# PIC32MX370F512L register map
Registers are 32-bit, access not given, reset 0x0 unless marked. A register's access mark holds for its fields unless they carry their own. Offsets are from the block's base; [hi:lo] are bit positions; {n}, {i} and the like mark numbered series; 'fields as' and 'values as' point back to an identical list.

## PMP — PMP peripheral
Base 0xBF807000
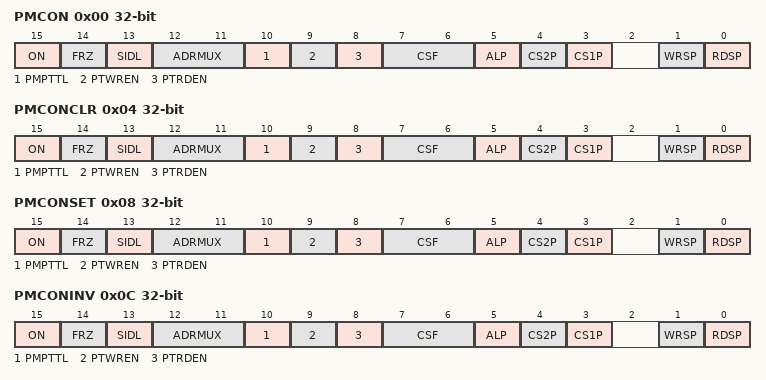
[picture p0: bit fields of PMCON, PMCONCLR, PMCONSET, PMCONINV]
0x00 PMCON
  [15] ON, [14] FRZ, [13] SIDL, [12:11] ADRMUX, [10] PMPTTL, [9] PTWREN, [8] PTRDEN, [7:6] CSF, [5] ALP, [4] CS2P, [3] CS1P, [1] WRSP, [0] RDSP
0x04 PMCONCLR
  fields as PMCON
0x08 PMCONSET
  fields as PMCON
0x0C PMCONINV
  fields as PMCON
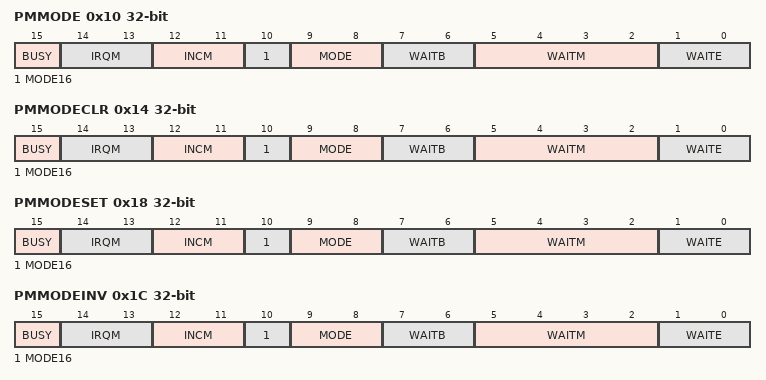
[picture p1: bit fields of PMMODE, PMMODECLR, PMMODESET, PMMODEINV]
0x10 PMMODE
  [15] BUSY, [14:13] IRQM, [12:11] INCM, [10] MODE16, [9:8] MODE, [7:6] WAITB, [5:2] WAITM, [1:0] WAITE
0x14 PMMODECLR
  fields as PMMODE
0x18 PMMODESET
  fields as PMMODE
0x1C PMMODEINV
  fields as PMMODE
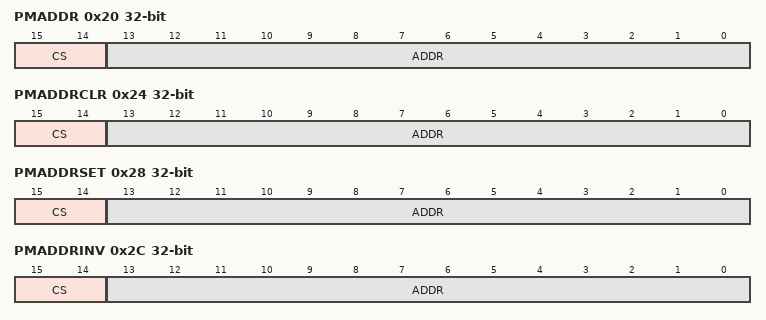
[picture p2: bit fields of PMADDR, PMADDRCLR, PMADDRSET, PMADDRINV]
0x20 PMADDR
  [15:14] CS, [13:0] ADDR
0x24 PMADDRCLR
  [15:14] CS, [13:0] ADDR
0x28 PMADDRSET
  [15:14] CS, [13:0] ADDR
0x2C PMADDRINV
  [15:14] CS, [13:0] ADDR
0x30 PMDOUT
  [31:0] DATAOUT
0x34 PMDOUTCLR
  [31:0] DATAOUT
0x38 PMDOUTSET
  [31:0] DATAOUT
0x3C PMDOUTINV
  [31:0] DATAOUT
0x40 PMDIN
  [31:0] DATAIN
0x44 PMDINCLR
  [31:0] DATAIN
0x48 PMDINSET
  [31:0] DATAIN
0x4C PMDININV
  [31:0] DATAIN
0x50 PMAEN
  [15:0] PTEN
0x54 PMAENCLR
  [15:0] PTEN
0x58 PMAENSET
  [15:0] PTEN
0x5C PMAENINV
  [15:0] PTEN
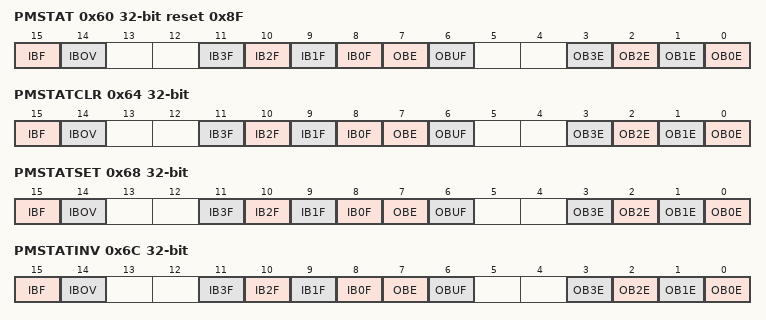
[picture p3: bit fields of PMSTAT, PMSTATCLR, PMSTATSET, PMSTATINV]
0x60 PMSTAT reset 0x8F
  [15] IBF, [14] IBOV, [n+8] IB{n}F (n=0..3), [7] OBE, [6] OBUF, [n] OB{n}E (n=0..3)
0x64 PMSTATCLR
  fields as PMSTAT
0x68 PMSTATSET
  fields as PMSTAT
0x6C PMSTATINV
  fields as PMSTAT

## ADC10 — ADC10 peripheral
Base 0xBF809000
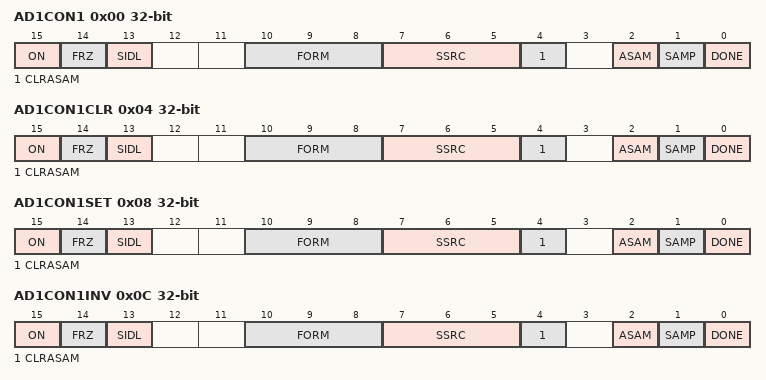
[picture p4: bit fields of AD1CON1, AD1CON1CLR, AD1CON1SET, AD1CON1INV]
0x00 AD1CON1
  [15] ON, [14] FRZ, [13] SIDL, [10:8] FORM, [7:5] SSRC, [4] CLRASAM, [2] ASAM, [1] SAMP, [0] DONE
0x04 AD1CON1CLR
  fields as AD1CON1
0x08 AD1CON1SET
  fields as AD1CON1
0x0C AD1CON1INV
  fields as AD1CON1
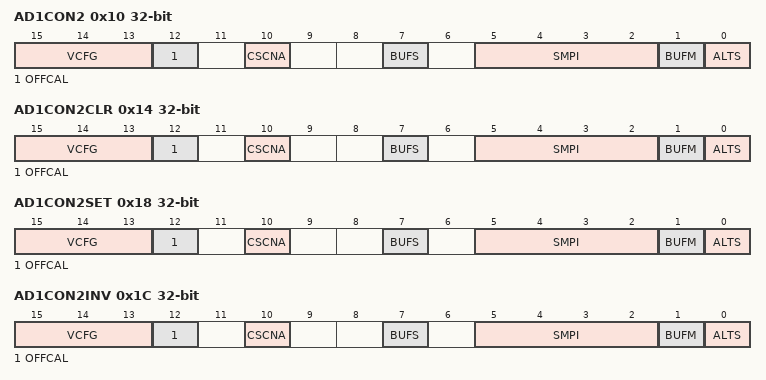
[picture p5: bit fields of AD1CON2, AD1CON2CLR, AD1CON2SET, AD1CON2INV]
0x10 AD1CON2
  [15:13] VCFG, [12] OFFCAL, [10] CSCNA, [7] BUFS, [5:2] SMPI, [1] BUFM, [0] ALTS
0x14 AD1CON2CLR
  fields as AD1CON2
0x18 AD1CON2SET
  fields as AD1CON2
0x1C AD1CON2INV
  fields as AD1CON2
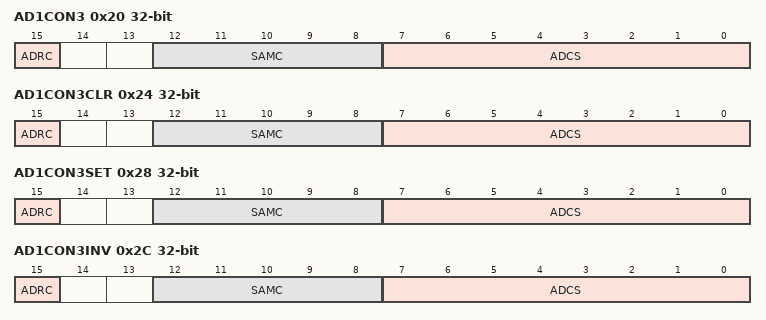
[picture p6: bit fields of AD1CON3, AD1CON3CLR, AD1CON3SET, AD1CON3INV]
0x20 AD1CON3
  [15] ADRC, [12:8] SAMC, [7:0] ADCS
0x24 AD1CON3CLR
  [15] ADRC, [12:8] SAMC, [7:0] ADCS
0x28 AD1CON3SET
  [15] ADRC, [12:8] SAMC, [7:0] ADCS
0x2C AD1CON3INV
  [15] ADRC, [12:8] SAMC, [7:0] ADCS
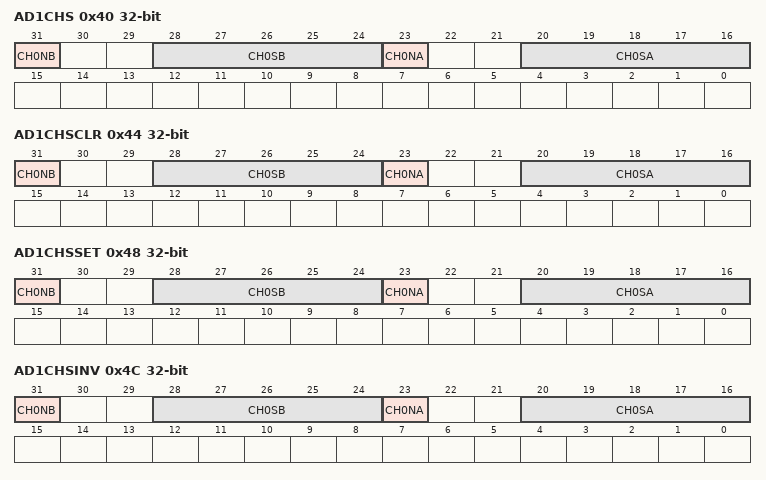
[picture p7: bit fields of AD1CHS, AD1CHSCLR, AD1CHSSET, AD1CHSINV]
0x40 AD1CHS
  [31] CH0NB, [28:24] CH0SB, [23] CH0NA, [20:16] CH0SA
0x44 AD1CHSCLR
  [31] CH0NB, [28:24] CH0SB, [23] CH0NA, [20:16] CH0SA
0x48 AD1CHSSET
  [31] CH0NB, [28:24] CH0SB, [23] CH0NA, [20:16] CH0SA
0x4C AD1CHSINV
  [31] CH0NB, [28:24] CH0SB, [23] CH0NA, [20:16] CH0SA
0x50 AD1CSSL
  [30:0] CSSL
0x54 AD1CSSLCLR
  [30:0] CSSL
0x58 AD1CSSLSET
  [30:0] CSSL
0x5C AD1CSSLINV
  [30:0] CSSL
{0x70+0x10*i} ADC1BUF{i} (i=0..9)
0x110 ADC1BUFA
0x120 ADC1BUFB
0x130 ADC1BUFC
0x140 ADC1BUFD
0x150 ADC1BUFE
0x160 ADC1BUFF

## CVR — CVR peripheral
Base 0xBF809800
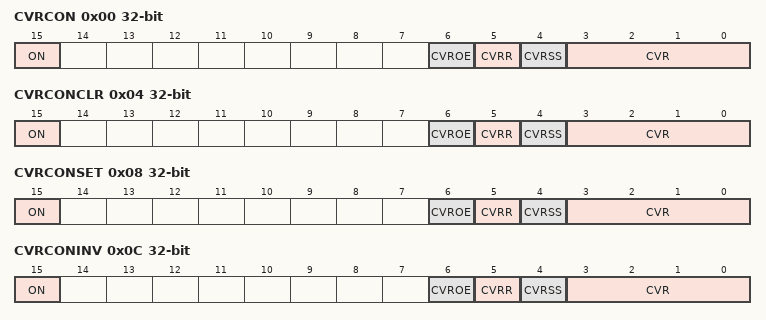
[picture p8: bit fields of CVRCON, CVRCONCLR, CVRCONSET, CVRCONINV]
0x00 CVRCON
  [15] ON, [6] CVROE, [5] CVRR, [4] CVRSS, [3:0] CVR
0x04 CVRCONCLR
  [15] ON, [6] CVROE, [5] CVRR, [4] CVRSS, [3:0] CVR
0x08 CVRCONSET
  [15] ON, [6] CVROE, [5] CVRR, [4] CVRSS, [3:0] CVR
0x0C CVRCONINV
  [15] ON, [6] CVROE, [5] CVRR, [4] CVRSS, [3:0] CVR

## CMP1 — CMP1 peripheral
Base 0xBF80A000
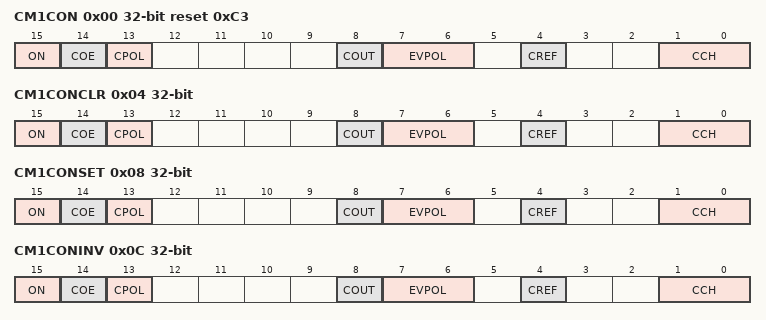
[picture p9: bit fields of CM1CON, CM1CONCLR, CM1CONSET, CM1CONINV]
0x00 CM1CON reset 0xC3
  [15] ON, [14] COE, [13] CPOL, [8] COUT, [7:6] EVPOL, [4] CREF, [1:0] CCH
0x04 CM1CONCLR
  fields as CM1CON
0x08 CM1CONSET
  fields as CM1CON
0x0C CM1CONINV
  fields as CM1CON

## CMP2 — CMP2 peripheral
Base 0xBF80A010
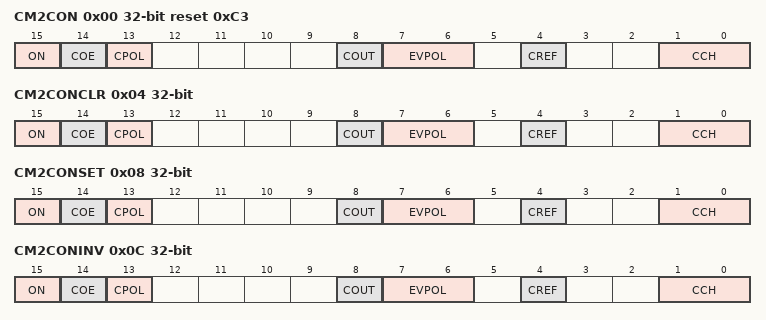
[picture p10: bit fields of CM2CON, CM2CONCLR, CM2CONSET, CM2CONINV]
0x00 CM2CON reset 0xC3
  [15] ON, [14] COE, [13] CPOL, [8] COUT, [7:6] EVPOL, [4] CREF, [1:0] CCH
0x04 CM2CONCLR
  fields as CM2CON
0x08 CM2CONSET
  fields as CM2CON
0x0C CM2CONINV
  fields as CM2CON

## CMP — CMP peripheral
Base 0xBF80A060
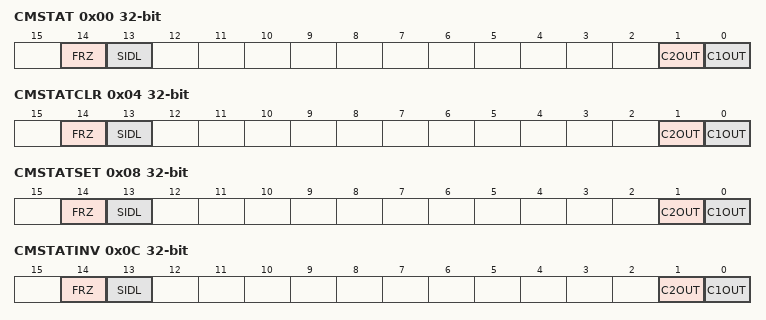
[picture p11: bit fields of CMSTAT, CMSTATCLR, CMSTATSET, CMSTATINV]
0x00 CMSTAT
  [14] FRZ, [13] SIDL, [1] C2OUT, [0] C1OUT
0x04 CMSTATCLR
  [14] FRZ, [13] SIDL, [1] C2OUT, [0] C1OUT
0x08 CMSTATSET
  [14] FRZ, [13] SIDL, [1] C2OUT, [0] C1OUT
0x0C CMSTATINV
  [14] FRZ, [13] SIDL, [1] C2OUT, [0] C1OUT

## CTMU — CTMU peripheral
Base 0xBF80A200
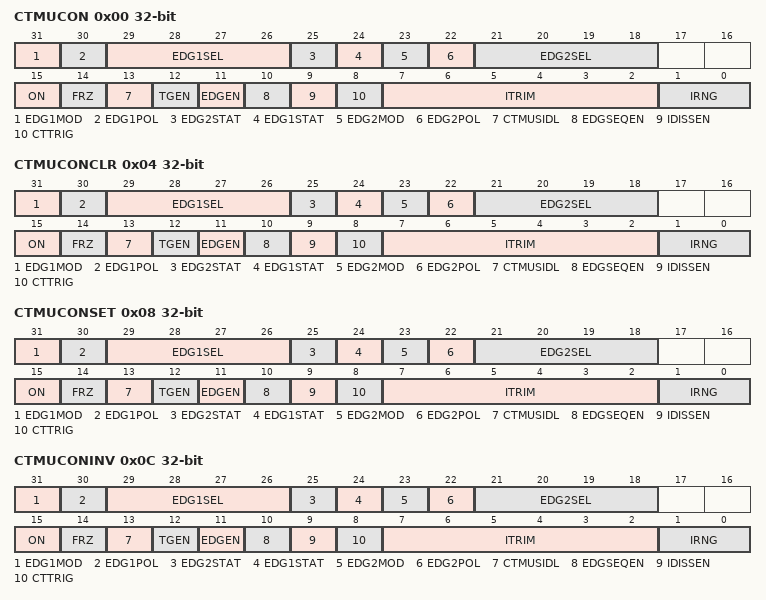
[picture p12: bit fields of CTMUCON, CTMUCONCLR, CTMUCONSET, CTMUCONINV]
0x00 CTMUCON
  [31] EDG1MOD, [30] EDG1POL, [29:26] EDG1SEL, [25] EDG2STAT, [24] EDG1STAT, [23] EDG2MOD, [22] EDG2POL, [21:18] EDG2SEL, [15] ON, [14] FRZ, [13] CTMUSIDL, [12] TGEN, [11] EDGEN, [10] EDGSEQEN, [9] IDISSEN, [8] CTTRIG, [7:2] ITRIM, [1:0] IRNG
0x04 CTMUCONCLR
  fields as CTMUCON
0x08 CTMUCONSET
  fields as CTMUCON
0x0C CTMUCONINV
  fields as CTMUCON
